# CBASS0_QOS register map
Vendor: Texas Instruments
Peripheral module from a debugger description file (folder am243x).
Registers are 32-bit, read-write, reset 0x7000 unless marked. A register's access mark holds for its fields unless they carry their own. Offsets are as the file gives them; lines under a group give offsets from that group; [hi:lo] are bit positions; {n}, {i} and the like mark numbered series; 'fields as' and 'values as' point back to an identical list; <NAME> marks a mode.

## CBASS0_QOS
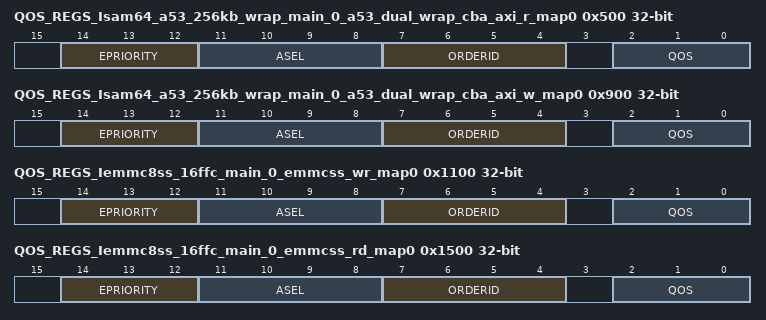
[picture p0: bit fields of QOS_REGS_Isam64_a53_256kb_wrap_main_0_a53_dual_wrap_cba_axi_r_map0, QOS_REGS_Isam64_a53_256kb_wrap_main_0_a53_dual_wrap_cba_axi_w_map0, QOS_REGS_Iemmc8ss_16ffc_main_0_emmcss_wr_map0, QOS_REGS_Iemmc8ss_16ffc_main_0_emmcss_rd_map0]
0x500 QOS_REGS_Isam64_a53_256kb_wrap_main_0_a53_dual_wrap_cba_axi_r_map0 — The Map Register defines the fields for the master Isam64_a53_256kb_wrap_main_0.a53_dual_wrap_cba_axi_r per channel.
  [14:12] EPRIORITY — epriority signal for channel N.
  [11:8] ASEL — asel signal for channel N. 0 = SOC address. 1-15 = peripheral address.
  [7:4] ORDERID — orderid signal for channel N.
  [2:0] QOS — qos signal for channel N.
0x900 QOS_REGS_Isam64_a53_256kb_wrap_main_0_a53_dual_wrap_cba_axi_w_map0 — The Map Register defines the fields for the master Isam64_a53_256kb_wrap_main_0.a53_dual_wrap_cba_axi_w per channel.
  fields as QOS_REGS_Isam64_a53_256kb_wrap_main_0_a53_dual_wrap_cba_axi_r_map0
0x1100 QOS_REGS_Iemmc8ss_16ffc_main_0_emmcss_wr_map0 — The Map Register defines the fields for the master Iemmc8ss_16ffc_main_0.emmcss_wr per channel.
  fields as QOS_REGS_Isam64_a53_256kb_wrap_main_0_a53_dual_wrap_cba_axi_r_map0
0x1500 QOS_REGS_Iemmc8ss_16ffc_main_0_emmcss_rd_map0 — The Map Register defines the fields for the master Iemmc8ss_16ffc_main_0.emmcss_rd per channel.
  fields as QOS_REGS_Isam64_a53_256kb_wrap_main_0_a53_dual_wrap_cba_axi_r_map0
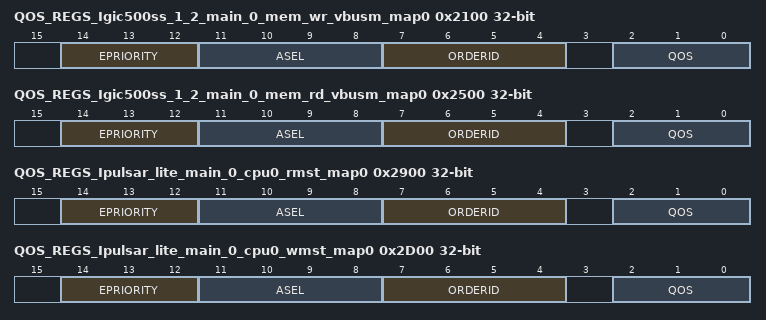
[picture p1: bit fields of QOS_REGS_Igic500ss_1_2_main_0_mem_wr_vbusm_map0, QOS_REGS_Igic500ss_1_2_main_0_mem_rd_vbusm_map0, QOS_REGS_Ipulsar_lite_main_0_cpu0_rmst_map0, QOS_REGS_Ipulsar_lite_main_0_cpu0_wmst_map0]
0x2100 QOS_REGS_Igic500ss_1_2_main_0_mem_wr_vbusm_map0 — The Map Register defines the fields for the master Igic500ss_1_2_main_0.mem_wr_vbusm per channel.
  fields as QOS_REGS_Isam64_a53_256kb_wrap_main_0_a53_dual_wrap_cba_axi_r_map0
0x2500 QOS_REGS_Igic500ss_1_2_main_0_mem_rd_vbusm_map0 — The Map Register defines the fields for the master Igic500ss_1_2_main_0.mem_rd_vbusm per channel.
  fields as QOS_REGS_Isam64_a53_256kb_wrap_main_0_a53_dual_wrap_cba_axi_r_map0
0x2900 QOS_REGS_Ipulsar_lite_main_0_cpu0_rmst_map0 — The Map Register defines the fields for the master Ipulsar_lite_main_0.cpu0_rmst per channel.
  fields as QOS_REGS_Isam64_a53_256kb_wrap_main_0_a53_dual_wrap_cba_axi_r_map0
0x2D00 QOS_REGS_Ipulsar_lite_main_0_cpu0_wmst_map0 — The Map Register defines the fields for the master Ipulsar_lite_main_0.cpu0_wmst per channel.
  fields as QOS_REGS_Isam64_a53_256kb_wrap_main_0_a53_dual_wrap_cba_axi_r_map0
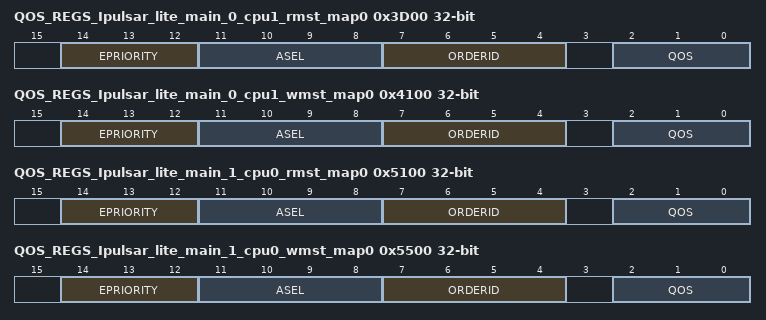
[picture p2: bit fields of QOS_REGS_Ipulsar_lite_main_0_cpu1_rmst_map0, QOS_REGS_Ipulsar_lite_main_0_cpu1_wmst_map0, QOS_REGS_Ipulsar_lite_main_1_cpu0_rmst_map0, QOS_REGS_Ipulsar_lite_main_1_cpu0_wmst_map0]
0x3D00 QOS_REGS_Ipulsar_lite_main_0_cpu1_rmst_map0 — The Map Register defines the fields for the master Ipulsar_lite_main_0.cpu1_rmst per channel.
  fields as QOS_REGS_Isam64_a53_256kb_wrap_main_0_a53_dual_wrap_cba_axi_r_map0
0x4100 QOS_REGS_Ipulsar_lite_main_0_cpu1_wmst_map0 — The Map Register defines the fields for the master Ipulsar_lite_main_0.cpu1_wmst per channel.
  fields as QOS_REGS_Isam64_a53_256kb_wrap_main_0_a53_dual_wrap_cba_axi_r_map0
0x5100 QOS_REGS_Ipulsar_lite_main_1_cpu0_rmst_map0 — The Map Register defines the fields for the master Ipulsar_lite_main_1.cpu0_rmst per channel.
  fields as QOS_REGS_Isam64_a53_256kb_wrap_main_0_a53_dual_wrap_cba_axi_r_map0
0x5500 QOS_REGS_Ipulsar_lite_main_1_cpu0_wmst_map0 — The Map Register defines the fields for the master Ipulsar_lite_main_1.cpu0_wmst per channel.
  fields as QOS_REGS_Isam64_a53_256kb_wrap_main_0_a53_dual_wrap_cba_axi_r_map0
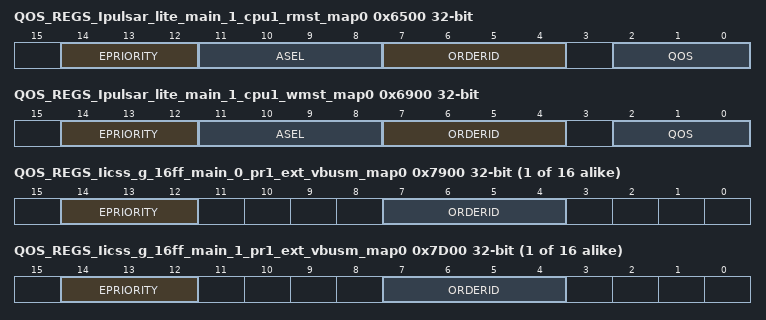
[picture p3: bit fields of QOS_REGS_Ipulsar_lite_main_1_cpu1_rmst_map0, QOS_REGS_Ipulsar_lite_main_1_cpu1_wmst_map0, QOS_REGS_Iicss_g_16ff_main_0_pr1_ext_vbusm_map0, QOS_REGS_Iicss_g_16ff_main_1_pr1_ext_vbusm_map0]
0x6500 QOS_REGS_Ipulsar_lite_main_1_cpu1_rmst_map0 — The Map Register defines the fields for the master Ipulsar_lite_main_1.cpu1_rmst per channel.
  fields as QOS_REGS_Isam64_a53_256kb_wrap_main_0_a53_dual_wrap_cba_axi_r_map0
0x6900 QOS_REGS_Ipulsar_lite_main_1_cpu1_wmst_map0 — The Map Register defines the fields for the master Ipulsar_lite_main_1.cpu1_wmst per channel.
  fields as QOS_REGS_Isam64_a53_256kb_wrap_main_0_a53_dual_wrap_cba_axi_r_map0
{0x7900+4i} QOS_REGS_Iicss_g_16ff_main_0_pr1_ext_vbusm_map{i} (i=0..15) — The Map Register defines the fields for the master Iicss_g_16ff_main_0.pr1_ext_vbusm per channel.
  [14:12] EPRIORITY — epriority signal for channel N.
  [7:4] ORDERID — orderid signal for channel N.
{0x7D00+4i} QOS_REGS_Iicss_g_16ff_main_1_pr1_ext_vbusm_map{i} (i=0..15) — The Map Register defines the fields for the master Iicss_g_16ff_main_1.pr1_ext_vbusm per channel.
  fields as QOS_REGS_Iicss_g_16ff_main_0_pr1_ext_vbusm_map0
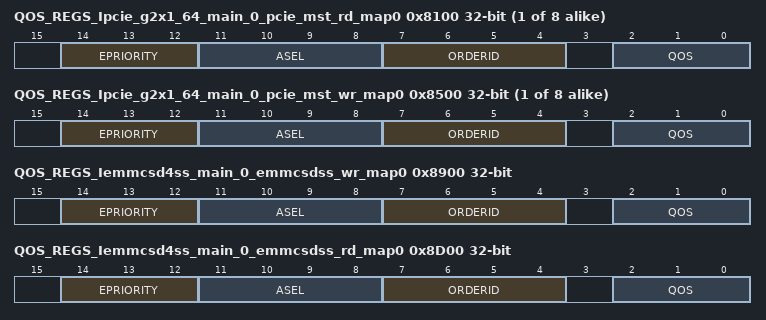
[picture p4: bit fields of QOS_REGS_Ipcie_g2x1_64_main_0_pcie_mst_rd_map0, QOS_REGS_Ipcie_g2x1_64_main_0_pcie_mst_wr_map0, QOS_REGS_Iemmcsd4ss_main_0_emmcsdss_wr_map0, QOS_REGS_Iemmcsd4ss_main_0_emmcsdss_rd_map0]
{0x8100+4i} QOS_REGS_Ipcie_g2x1_64_main_0_pcie_mst_rd_map{i} (i=0..7) — The Map Register defines the fields for the master Ipcie_g2x1_64_main_0.pcie_mst_rd per channel.
  fields as QOS_REGS_Isam64_a53_256kb_wrap_main_0_a53_dual_wrap_cba_axi_r_map0
{0x8500+4i} QOS_REGS_Ipcie_g2x1_64_main_0_pcie_mst_wr_map{i} (i=0..7) — The Map Register defines the fields for the master Ipcie_g2x1_64_main_0.pcie_mst_wr per channel.
  fields as QOS_REGS_Isam64_a53_256kb_wrap_main_0_a53_dual_wrap_cba_axi_r_map0
0x8900 QOS_REGS_Iemmcsd4ss_main_0_emmcsdss_wr_map0 — The Map Register defines the fields for the master Iemmcsd4ss_main_0.emmcsdss_wr per channel.
  fields as QOS_REGS_Isam64_a53_256kb_wrap_main_0_a53_dual_wrap_cba_axi_r_map0
0x8D00 QOS_REGS_Iemmcsd4ss_main_0_emmcsdss_rd_map0 — The Map Register defines the fields for the master Iemmcsd4ss_main_0.emmcsdss_rd per channel.
  fields as QOS_REGS_Isam64_a53_256kb_wrap_main_0_a53_dual_wrap_cba_axi_r_map0
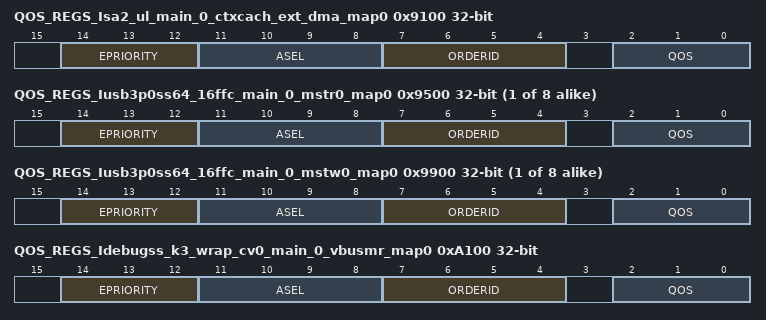
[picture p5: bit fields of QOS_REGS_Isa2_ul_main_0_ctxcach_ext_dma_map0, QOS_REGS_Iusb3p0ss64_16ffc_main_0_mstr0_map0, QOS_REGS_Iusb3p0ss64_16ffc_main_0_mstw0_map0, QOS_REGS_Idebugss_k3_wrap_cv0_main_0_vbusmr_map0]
0x9100 QOS_REGS_Isa2_ul_main_0_ctxcach_ext_dma_map0 — The Map Register defines the fields for the master Isa2_ul_main_0.ctxcach_ext_dma per channel.
  fields as QOS_REGS_Isam64_a53_256kb_wrap_main_0_a53_dual_wrap_cba_axi_r_map0
{0x9500+4i} QOS_REGS_Iusb3p0ss64_16ffc_main_0_mstr0_map{i} (i=0..7) — The Map Register defines the fields for the master Iusb3p0ss64_16ffc_main_0.mstr0 per channel.
  fields as QOS_REGS_Isam64_a53_256kb_wrap_main_0_a53_dual_wrap_cba_axi_r_map0
{0x9900+4i} QOS_REGS_Iusb3p0ss64_16ffc_main_0_mstw0_map{i} (i=0..7) — The Map Register defines the fields for the master Iusb3p0ss64_16ffc_main_0.mstw0 per channel.
  fields as QOS_REGS_Isam64_a53_256kb_wrap_main_0_a53_dual_wrap_cba_axi_r_map0
0xA100 QOS_REGS_Idebugss_k3_wrap_cv0_main_0_vbusmr_map0 — The Map Register defines the fields for the master Idebugss_k3_wrap_cv0_main_0.vbusmr per channel.
  fields as QOS_REGS_Isam64_a53_256kb_wrap_main_0_a53_dual_wrap_cba_axi_r_map0
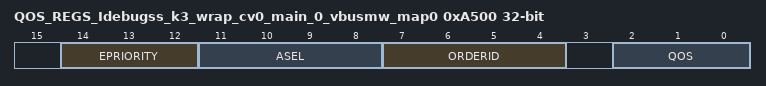
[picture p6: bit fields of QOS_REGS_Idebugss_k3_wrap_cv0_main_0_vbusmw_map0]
0xA500 QOS_REGS_Idebugss_k3_wrap_cv0_main_0_vbusmw_map0 — The Map Register defines the fields for the master Idebugss_k3_wrap_cv0_main_0.vbusmw per channel.
  fields as QOS_REGS_Isam64_a53_256kb_wrap_main_0_a53_dual_wrap_cba_axi_r_map0
